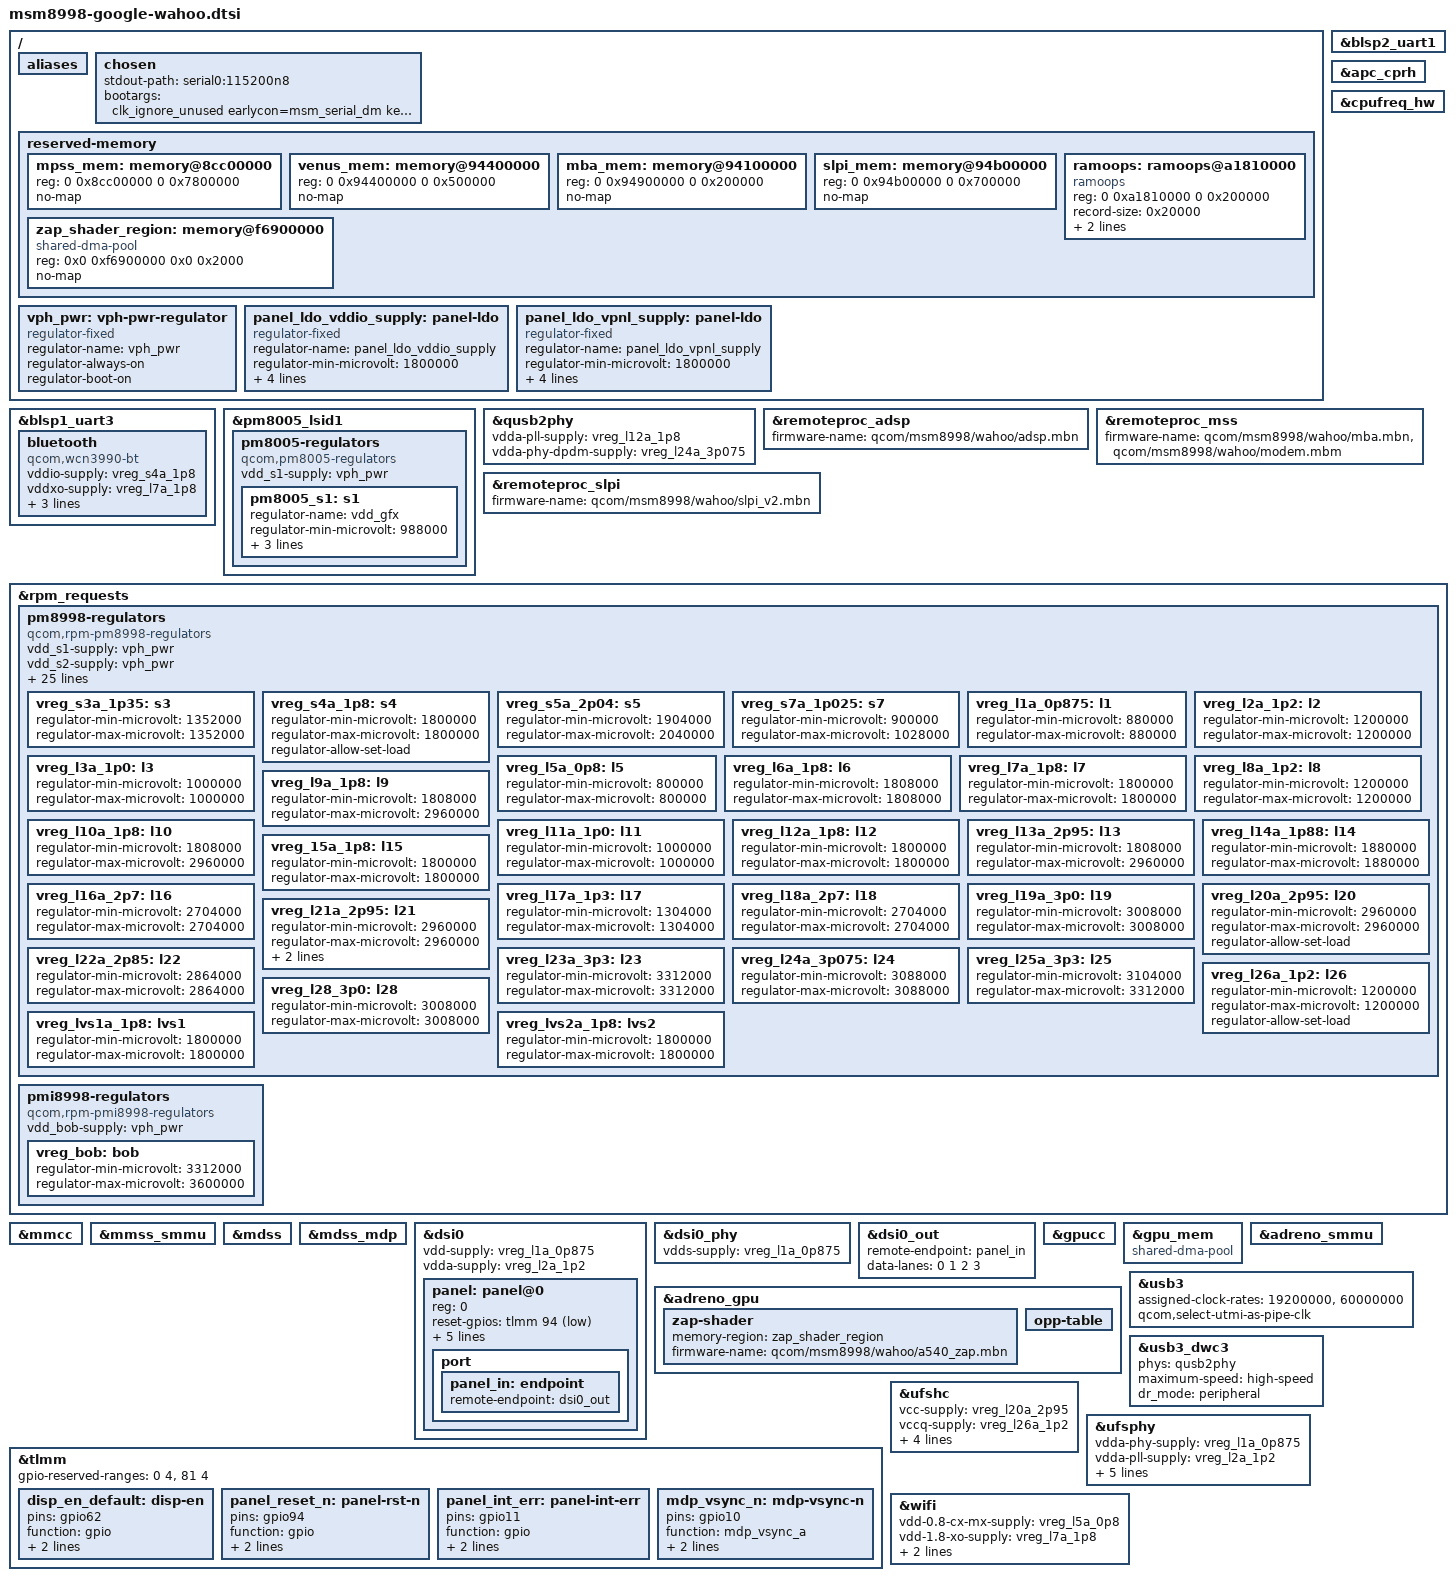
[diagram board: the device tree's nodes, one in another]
// SPDX-License-Identifier: GPL-2.0
/* Copyright (c) 2020 Caleb Connolly <caleb@connolly.tech> */

#include "msm8998.dtsi"
#include "pm8998.dtsi"
#include "pmi8998.dtsi"
#include "pm8005.dtsi"

/delete-node/ &mpss_mem;
/delete-node/ &venus_mem;
/delete-node/ &mba_mem;
/delete-node/ &slpi_mem;

/ {
	aliases {
	};

	chosen {
		#address-cells = <2>;
		#size-cells = <2>;
		ranges;

		stdout-path = "serial0:115200n8";

		bootargs = "clk_ignore_unused earlycon=msm_serial_dm keep_bootcon console=ttyGS0,115200 console=ttyMSM1,115200";
	};

	reserved-memory {
		#address-cells = <2>;
 		#size-cells = <2>;
 		ranges;

		mpss_mem: memory@8cc00000 {
			reg = <0 0x8cc00000 0 0x7800000>;
			no-map;
		};

		venus_mem: memory@94400000 {
			reg = <0 0x94400000 0 0x500000>;
			no-map;
		};

		mba_mem: memory@94100000 {
			reg = <0 0x94900000 0 0x200000>;
			no-map;
		};

		slpi_mem: memory@94b00000 {
			reg = <0 0x94b00000 0 0x700000>;
			no-map;
		};

		ramoops: ramoops@a1810000 {
			compatible = "ramoops";
			reg = <0 0xa1810000 0 0x200000>;
			record-size = <0x20000>;
			console-size = <0x100000>;
			pmsg-size = <0x80000>;
		};

		zap_shader_region: memory@f6900000 {
			compatible = "shared-dma-pool";
			reg = <0x0 0xf6900000 0x0 0x2000>;
			no-map;
		};
	};

	vph_pwr: vph-pwr-regulator {
		compatible = "regulator-fixed";
		regulator-name = "vph_pwr";
		regulator-always-on;
		regulator-boot-on;
	};

	panel_ldo_vddio_supply: panel-ldo {
		compatible = "regulator-fixed";
		regulator-name = "panel_ldo_vddio_supply";

		regulator-min-microvolt = <1800000>;
		regulator-max-microvolt = <1800000>;

		gpio = <&tlmm 133 0>;
		enable-active-high;
		regulator-boot-on;
	};

	panel_ldo_vpnl_supply: panel-ldo {
		compatible = "regulator-fixed";
		regulator-name = "panel_ldo_vpnl_supply";

		regulator-min-microvolt = <1800000>;
		regulator-max-microvolt = <1800000>;

		gpio = <&tlmm 21 0>;
		enable-active-high;
		regulator-boot-on;
	};
};

&blsp2_uart1 {
	status = "okay";
};

&blsp1_uart3 {
	status = "okay";

	bluetooth {
		compatible = "qcom,wcn3990-bt";

		vddio-supply = <&vreg_s4a_1p8>;
		vddxo-supply = <&vreg_l7a_1p8>;
		vddrf-supply = <&vreg_l17a_1p3>;
		vddch0-supply = <&vreg_l25a_3p3>;
		max-speed = <3200000>;
	};
};

&apc_cprh {
	status = "okay";
};

&cpufreq_hw {
	status = "okay";
};

&pm8005_lsid1 {
	pm8005-regulators {
		compatible = "qcom,pm8005-regulators";

		vdd_s1-supply = <&vph_pwr>;

		pm8005_s1: s1 {
			regulator-name = "vdd_gfx";
			regulator-min-microvolt = <524000>;
			regulator-max-microvolt = <1100000>;
			regulator-enable-ramp-delay = <500>;

			/* hack until we rig up the gpu consumer */
			regulator-always-on;
		};
	};
};

&qusb2phy {
	status = "okay";

	vdda-pll-supply = <&vreg_l12a_1p8>;
	vdda-phy-dpdm-supply = <&vreg_l24a_3p075>;
};

&remoteproc_adsp {
	status = "okay";

	firmware-name = "qcom/msm8998/wahoo/adsp.mbn";
};

&remoteproc_mss {
	firmware-name = "qcom/msm8998/wahoo/mba.mbn",
	                "qcom/msm8998/wahoo/modem.mbm";
};

&remoteproc_slpi {
	status = "okay";

	firmware-name = "qcom/msm8998/wahoo/slpi_v2.mbn";
};

&rpm_requests {
	pm8998-regulators {
		compatible = "qcom,rpm-pm8998-regulators";

		vdd_s1-supply = <&vph_pwr>;
		vdd_s2-supply = <&vph_pwr>;
		vdd_s3-supply = <&vph_pwr>;
		vdd_s4-supply = <&vph_pwr>;
		vdd_s5-supply = <&vph_pwr>;
		vdd_s6-supply = <&vph_pwr>;
		vdd_s7-supply = <&vph_pwr>;
		vdd_s8-supply = <&vph_pwr>;
		vdd_s9-supply = <&vph_pwr>;
		vdd_s10-supply = <&vph_pwr>;
		vdd_s11-supply = <&vph_pwr>;
		vdd_s12-supply = <&vph_pwr>;
		vdd_s13-supply = <&vph_pwr>;
		vdd_l1_l27-supply = <&vreg_s7a_1p025>;
		vdd_l2_l8_l17-supply = <&vreg_s3a_1p35>;
		vdd_l3_l11-supply = <&vreg_s7a_1p025>;
		vdd_l4_l5-supply = <&vreg_s7a_1p025>;
		vdd_l6-supply = <&vreg_s5a_2p04>;
		vdd_l7_l12_l14_l15-supply = <&vreg_s5a_2p04>;
		vdd_l9-supply = <&vreg_bob>;
		vdd_l10_l23_l25-supply = <&vreg_bob>;
		vdd_l13_l19_l21-supply = <&vreg_bob>;
		vdd_l16_l28-supply = <&vreg_bob>;
		vdd_l18_l22-supply = <&vreg_bob>;
		vdd_l20_l24-supply = <&vreg_bob>;
		vdd_l26-supply = <&vreg_s3a_1p35>;
		vdd_lvs1_lvs2-supply = <&vreg_s4a_1p8>;

		vreg_s3a_1p35: s3 {
			regulator-min-microvolt = <1352000>;
			regulator-max-microvolt = <1352000>;
		};
		vreg_s4a_1p8: s4 {
			regulator-min-microvolt = <1800000>;
			regulator-max-microvolt = <1800000>;
			regulator-allow-set-load;
		};
		vreg_s5a_2p04: s5 {
			regulator-min-microvolt = <1904000>;
			regulator-max-microvolt = <2040000>;
		};
		vreg_s7a_1p025: s7 {
			regulator-min-microvolt = <900000>;
			regulator-max-microvolt = <1028000>;
		};
		vreg_l1a_0p875: l1 {
			regulator-min-microvolt = <880000>;
			regulator-max-microvolt = <880000>;
		};
		vreg_l2a_1p2: l2 {
			regulator-min-microvolt = <1200000>;
			regulator-max-microvolt = <1200000>;
		};
		vreg_l3a_1p0: l3 {
			regulator-min-microvolt = <1000000>;
			regulator-max-microvolt = <1000000>;
		};
		vreg_l5a_0p8: l5 {
			regulator-min-microvolt = <800000>;
			regulator-max-microvolt = <800000>;
		};
		vreg_l6a_1p8: l6 {
			regulator-min-microvolt = <1808000>;
			regulator-max-microvolt = <1808000>;
		};
		vreg_l7a_1p8: l7 {
			regulator-min-microvolt = <1800000>;
			regulator-max-microvolt = <1800000>;
		};
		vreg_l8a_1p2: l8 {
			regulator-min-microvolt = <1200000>;
			regulator-max-microvolt = <1200000>;
		};
		vreg_l9a_1p8: l9 {
			regulator-min-microvolt = <1808000>;
			regulator-max-microvolt = <2960000>;
		};
		vreg_l10a_1p8: l10 {
			regulator-min-microvolt = <1808000>;
			regulator-max-microvolt = <2960000>;
		};
		vreg_l11a_1p0: l11 {
			regulator-min-microvolt = <1000000>;
			regulator-max-microvolt = <1000000>;
		};
		vreg_l12a_1p8: l12 {
			regulator-min-microvolt = <1800000>;
			regulator-max-microvolt = <1800000>;
		};
		vreg_l13a_2p95: l13 {
			regulator-min-microvolt = <1808000>;
			regulator-max-microvolt = <2960000>;
		};
		vreg_l14a_1p88: l14 {
			regulator-min-microvolt = <1880000>;
			regulator-max-microvolt = <1880000>;
		};
		vreg_15a_1p8: l15 {
			regulator-min-microvolt = <1800000>;
			regulator-max-microvolt = <1800000>;
		};
		vreg_l16a_2p7: l16 {
			regulator-min-microvolt = <2704000>;
			regulator-max-microvolt = <2704000>;
		};
		vreg_l17a_1p3: l17 {
			regulator-min-microvolt = <1304000>;
			regulator-max-microvolt = <1304000>;
		};
		vreg_l18a_2p7: l18 {
			regulator-min-microvolt = <2704000>;
			regulator-max-microvolt = <2704000>;
		};
		vreg_l19a_3p0: l19 {
			regulator-min-microvolt = <3008000>;
			regulator-max-microvolt = <3008000>;
		};
		vreg_l20a_2p95: l20 {
			regulator-min-microvolt = <2960000>;
			regulator-max-microvolt = <2960000>;
			regulator-allow-set-load;
		};
		vreg_l21a_2p95: l21 {
			regulator-min-microvolt = <2960000>;
			regulator-max-microvolt = <2960000>;
			regulator-allow-set-load;
			regulator-system-load = <800000>;
		};
		vreg_l22a_2p85: l22 {
			regulator-min-microvolt = <2864000>;
			regulator-max-microvolt = <2864000>;
		};
		vreg_l23a_3p3: l23 {
			regulator-min-microvolt = <3312000>;
			regulator-max-microvolt = <3312000>;
		};
		vreg_l24a_3p075: l24 {
			regulator-min-microvolt = <3088000>;
			regulator-max-microvolt = <3088000>;
		};
		vreg_l25a_3p3: l25 {
			regulator-min-microvolt = <3104000>;
			regulator-max-microvolt = <3312000>;
		};
		vreg_l26a_1p2: l26 {
			regulator-min-microvolt = <1200000>;
			regulator-max-microvolt = <1200000>;
			regulator-allow-set-load;
		};
		vreg_l28_3p0: l28 {
			regulator-min-microvolt = <3008000>;
			regulator-max-microvolt = <3008000>;
		};

		vreg_lvs1a_1p8: lvs1 {
			regulator-min-microvolt = <1800000>;
			regulator-max-microvolt = <1800000>;
		};

		vreg_lvs2a_1p8: lvs2 {
			regulator-min-microvolt = <1800000>;
			regulator-max-microvolt = <1800000>;
		};

	};

	pmi8998-regulators {
		compatible = "qcom,rpm-pmi8998-regulators";

		vdd_bob-supply = <&vph_pwr>;

		vreg_bob: bob {
			regulator-min-microvolt = <3312000>;
			regulator-max-microvolt = <3600000>;
		};
	};
};

&mmcc {
	status = "okay";
};

&mmss_smmu {
	status = "okay";
};

&mdss {
	status = "okay";
};

&mdss_mdp {
	status = "okay";
};

&dsi0 {
	#address-cells = <1>;
	#size-cells = <0>;
	status = "okay";

	vdd-supply = <&vreg_l1a_0p875>;
	vdda-supply = <&vreg_l2a_1p2>;

	panel: panel@0 {
		reg = <0>;

		reset-gpios = <&tlmm 94 GPIO_ACTIVE_LOW>;
		disp-te-gpios = <&tlmm 10 GPIO_ACTIVE_LOW>;

		vddio-supply = <&panel_ldo_vddio_supply>;
		vpnl-supply = <&panel_ldo_vpnl_supply>;

		pinctrl-names = "default";
		pinctrl-0 = <&panel_reset_n &disp_en_default &mdp_vsync_n>;

		port {
			panel_in: endpoint {
				remote-endpoint = <&dsi0_out>;
			};
		};
	};
};

&dsi0_phy {
	status = "okay";
	vdds-supply = <&vreg_l1a_0p875>;
};

&dsi0_out {
	remote-endpoint = <&panel_in>;
	data-lanes = <0 1 2 3>;
};

/* Adreno 540 GPU */
&gpucc {
	status = "okay";
};

&gpu_mem {
	compatible = "shared-dma-pool";
};

&adreno_gpu {
	status = "okay";

	zap-shader {
		memory-region = <&zap_shader_region>; // gpu_mem?
		firmware-name = "qcom/msm8998/wahoo/a540_zap.mbn";
	};

	/*
	 * We are lacking support for the GPU regulator. Hence, disable higher
	 * frequencies for now to prevent the platform from hanging on high
	 * graphics loads. Perhaps the pm8005_s1 voltage below could be
	 * adjusted but I'd rather not touch it.
	 */
	opp-table {
		/delete-node/ opp-710000097;
		/delete-node/ opp-670000048;
		/delete-node/ opp-596000097;
		/delete-node/ opp-515000097;
	};
};

&adreno_smmu {
	status = "okay";
};

/*
 * HACK: Shoot GPU voltage high to stabilize Adreno 540 at high frequencies
 *       until the GPU CPR is brought up.
 */
&pm8005_s1 {
	regulator-min-microvolt = <988000>; /* 0,524V -> 0,988V */
	//regulator-max-microvolt = <1100000>;
};

&tlmm {
	gpio-reserved-ranges = <0 4>, <81 4>;

	disp_en_default: disp-en {
		pins = "gpio62";
		function = "gpio";
		drive-strength = <8>;
		bias-disable;
	};

	panel_reset_n: panel-rst-n {
		pins = "gpio94";
		function = "gpio";
		drive-strength = <8>;
		bias-disable;
	};

	panel_int_err: panel-int-err {
		pins = "gpio11";
		function = "gpio";
		drive-strength = <2>;
		bias-pull-down;
	};

	mdp_vsync_n: mdp-vsync-n {
		pins = "gpio10";
		function = "mdp_vsync_a";
		drive-strength = <2>;
		bias-pull-down;
	};
};

/*
 * The device does contain a USB3 capable type-c port,
 * however it doesn't seem to work when superspeed mode is
 * enabled.
 */
&usb3 {
	status = "okay";

	/* Operate "GCC_USB30_MASTER_CLK" in HS mode (>=60 MHz) */
	assigned-clock-rates = <19200000>, <60000000>;

	/* Disable USB3 pipe_clk requirement */
	qcom,select-utmi-as-pipe-clk;
};

&usb3_dwc3 {
	/* Drop USB 3 SuperSpeed PHY to bring up the "usb0" interface */
	phys = <&qusb2phy>;
	phy-names = "usb2-phy";

	/* We can only operate at USB 2.0 speeds */
	maximum-speed = "high-speed";

	/* Force to peripheral until we have Type-C hooked up */
	dr_mode = "peripheral";
};

&ufshc {
	status = "okay";

	vcc-supply = <&vreg_l20a_2p95>;
	vccq-supply = <&vreg_l26a_1p2>;
	vccq2-supply = <&vreg_s4a_1p8>;
	vcc-max-microamp = <750000>;
	vccq-max-microamp = <560000>;
	vccq2-max-microamp = <750000>;
};

&ufsphy {
	status = "okay";

	vdda-phy-supply = <&vreg_l1a_0p875>;
	vdda-pll-supply = <&vreg_l2a_1p2>;
	vddp-ref-clk-supply = <&vreg_l26a_1p2>;
	vdda-phy-max-microamp = <51400>;
	vdda-pll-max-microamp = <14600>;
	vddp-ref-clk-max-microamp = <100>;
	vddp-ref-clk-always-on;
};

&wifi {
	status = "okay";

	vdd-0.8-cx-mx-supply = <&vreg_l5a_0p8>;
	vdd-1.8-xo-supply = <&vreg_l7a_1p8>;
	vdd-1.3-rfa-supply = <&vreg_l17a_1p3>;
	vdd-3.3-ch0-supply = <&vreg_l25a_3p3>;
};
